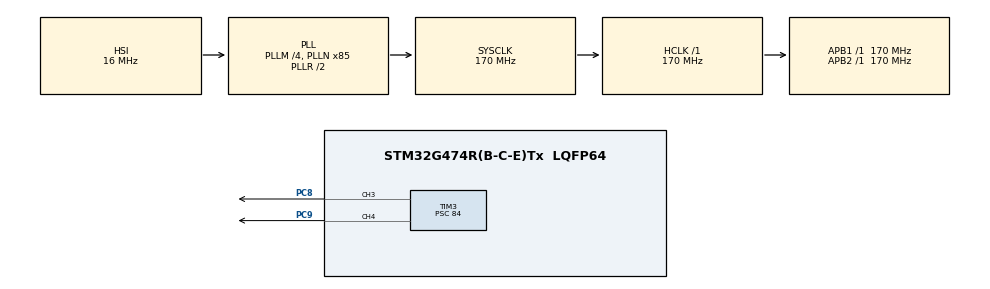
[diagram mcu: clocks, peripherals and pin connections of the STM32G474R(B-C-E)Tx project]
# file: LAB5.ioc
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Mcu.Family=STM32G4
Mcu.Name=STM32G474R(B-C-E)Tx
Mcu.Package=LQFP64
NVIC.PriorityGroup=NVIC_PRIORITYGROUP_4
PA13.GPIO_Label=T_SWDIO
PA13.Signal=SYS_JTMS-SWDIO
PA14.GPIO_Label=T_SWCLK
PA14.Signal=SYS_JTCK-SWCLK
PA2.GPIO_Label=LPUART1_TX [STLINKV3E_VCP_RX]
PA2.Signal=LPUART1_TX
PA3.GPIO_Label=LPUART1_RX [STLINKV3E_VCP_TX]
PA3.Signal=LPUART1_RX
PB3.GPIO_Label=T_SWO
PB3.Signal=SYS_JTDO-SWO
PC14-OSC32_IN.GPIO_Label=RCC_OSC32_IN
PC14-OSC32_IN.Signal=RCC_OSC32_IN
PC15-OSC32_OUT.GPIO_Label=RCC_OSC32_OUT
PC15-OSC32_OUT.Signal=RCC_OSC32_OUT
PC8.Signal=S_TIM3_CH3
PC9.Signal=S_TIM3_CH4
PF0-OSC_IN.GPIO_Label=RCC_OSC_IN
PF0-OSC_IN.Signal=RCC_OSC_IN
PF1-OSC_OUT.GPIO_Label=RCC_OSC_OUT
PF1-OSC_OUT.Signal=RCC_OSC_OUT
ProjectManager.HeapSize=0x200
ProjectManager.StackSize=0x400
ProjectManager.TargetToolchain=STM32CubeIDE
RCC.ADC12Freq_Value=170000000
RCC.ADC345Freq_Value=170000000
RCC.AHBFreq_Value=170000000
RCC.APB1Freq_Value=170000000
RCC.APB1TimFreq_Value=170000000
RCC.APB2Freq_Value=170000000
RCC.APB2TimFreq_Value=170000000
RCC.CortexFreq_Value=170000000
RCC.EXTERNAL_CLOCK_VALUE=12288000
RCC.HCLKFreq_Value=170000000
RCC.HSE_VALUE=24000000
RCC.HSI48_VALUE=48000000
RCC.HSI_VALUE=16000000
RCC.LSE_VALUE=32768
RCC.PLLM=RCC_PLLM_DIV4
RCC.PLLN=85
RCC.RTCClockSelection=RCC_RTCCLKSOURCE_LSE
RCC.SYSCLKFreq_VALUE=170000000
RCC.SYSCLKSource=RCC_SYSCLKSOURCE_PLLCLK
RCC.USBFreq_Value=170000000
RCC.VCOOutputFreq_Value=340000000
SH.S_TIM3_CH3.0=TIM3_CH3,PWM Generation3 CH3
SH.S_TIM3_CH4.0=TIM3_CH4,PWM Generation4 CH4
TIM3.Channel-PWM\ Generation3\ CH3=TIM_CHANNEL_3
TIM3.Channel-PWM\ Generation4\ CH4=TIM_CHANNEL_4
TIM3.PeriodNoDither=19999
TIM3.Prescaler=84
TIM3.PulseNoDither_3=4000
TIM3.PulseNoDither_4=16000
VP_SYS_VS_DBSignals.Mode=DisableDeadBatterySignals
VP_TIM3_VS_ClockSourceINT.Mode=Internal
board=NUCLEO-G474RE

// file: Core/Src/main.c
/* USER CODE BEGIN Header */
/**
  ******************************************************************************
  * @file           : main.c
  * @brief          : Main program body
  ******************************************************************************
  * @attention
  *
  * Copyright (c) 2026 STMicroelectronics.
  * All rights reserved.
  *
  * This software is licensed under terms that can be found in the LICENSE file
  * in the root directory of this software component.
  * If no LICENSE file comes with this software, it is provided AS-IS.
  *
  ******************************************************************************
  */
/* USER CODE END Header */
#include "main.h"

TIM_HandleTypeDef htim3;

void SystemClock_Config(void);
static void MX_GPIO_Init(void);
static void MX_TIM3_Init(void);

int main(void)
{

  /* MCU Configuration--------------------------------------------------------*/

  /* Reset of all peripherals, Initializes the Flash interface and the Systick. */
  HAL_Init();

  /* Configure the system clock */
  SystemClock_Config();

  /* Initialize all configured peripherals */
  MX_GPIO_Init();
  MX_TIM3_Init();
  /* USER CODE BEGIN 2 */
  HAL_TIM_PWM_Start(&htim3, TIM_CHANNEL_3);  // 啟動 TIM3_CH3 (PC8) 的 PWM 輸出

    uint32_t previous_time = 0;                // 記錄上次更新亮度的時間 (毫秒)
    int32_t pwm_value = 0;                     // 記錄目前的 CCR (亮度) 數值
    int32_t step = 200;
  /* USER CODE END 2 */

  /* Infinite loop */
  while (1)
  {

    /* USER CODE BEGIN 3 */
	  uint32_t current_time = HAL_GetTick();   // 取得目前的系統時間 (單位: 毫秒)

	      // 每 10 毫秒更新一次 PWM 數值 (非阻塞式寫法)
	      if (current_time - previous_time >= 10)
	      {
	        previous_time = current_time;          // 更新時間紀錄，為下一次 10ms 準備

	        pwm_value += step;                     // 將當前亮度加上步進值 (變亮或變暗)

	        // 如果亮度超過或等於 ARR 最大值 (19999)，或者降到 0 以下
	        if (pwm_value >= 19999)
	        {
	          pwm_value = 19999;                   // 限制最大值不超過 ARR
	          step = -step;                        // 反轉方向，準備變暗
	        }
	        else if (pwm_value <= 0)
	        {
	          pwm_value = 0;                       // 限制最小值不低於 0
	          step = -step;                        // 反轉方向，準備變亮
	        }

	        // 將計算好的新亮度寫入 CCR 暫存器，PWM 會即時改變 Duty Cycle
	        // (注意：這行已經正確包在 10ms 的 if 判斷式裡面了)
	        __HAL_TIM_SET_COMPARE(&htim3, TIM_CHANNEL_3, pwm_value);
	      }
  }
  /* USER CODE END 3 */
}

void SystemClock_Config(void)
{
  RCC_OscInitTypeDef RCC_OscInitStruct = {0};
  RCC_ClkInitTypeDef RCC_ClkInitStruct = {0};

  /** Configure the main internal regulator output voltage
  */
  HAL_PWREx_ControlVoltageScaling(PWR_REGULATOR_VOLTAGE_SCALE1_BOOST);

  /** Initializes the RCC Oscillators according to the specified parameters
  * in the RCC_OscInitTypeDef structure.
  */
  RCC_OscInitStruct.OscillatorType = RCC_OSCILLATORTYPE_HSI;
  RCC_OscInitStruct.HSIState = RCC_HSI_ON;
  RCC_OscInitStruct.HSICalibrationValue = RCC_HSICALIBRATION_DEFAULT;
  RCC_OscInitStruct.PLL.PLLState = RCC_PLL_ON;
  RCC_OscInitStruct.PLL.PLLSource = RCC_PLLSOURCE_HSI;
  RCC_OscInitStruct.PLL.PLLM = RCC_PLLM_DIV4;
  RCC_OscInitStruct.PLL.PLLN = 85;
  RCC_OscInitStruct.PLL.PLLP = RCC_PLLP_DIV2;
  RCC_OscInitStruct.PLL.PLLQ = RCC_PLLQ_DIV2;
  RCC_OscInitStruct.PLL.PLLR = RCC_PLLR_DIV2;
  if (HAL_RCC_OscConfig(&RCC_OscInitStruct) != HAL_OK)
  {
    Error_Handler();
  }

  /** Initializes the CPU, AHB and APB buses clocks
  */
  RCC_ClkInitStruct.ClockType = RCC_CLOCKTYPE_HCLK|RCC_CLOCKTYPE_SYSCLK
                              |RCC_CLOCKTYPE_PCLK1|RCC_CLOCKTYPE_PCLK2;
  RCC_ClkInitStruct.SYSCLKSource = RCC_SYSCLKSOURCE_PLLCLK;
  RCC_ClkInitStruct.AHBCLKDivider = RCC_SYSCLK_DIV1;
  RCC_ClkInitStruct.APB1CLKDivider = RCC_HCLK_DIV1;
  RCC_ClkInitStruct.APB2CLKDivider = RCC_HCLK_DIV1;

  if (HAL_RCC_ClockConfig(&RCC_ClkInitStruct, FLASH_LATENCY_4) != HAL_OK)
  {
    Error_Handler();
  }
}

static void MX_TIM3_Init(void)
{

  TIM_ClockConfigTypeDef sClockSourceConfig = {0};
  TIM_MasterConfigTypeDef sMasterConfig = {0};
  TIM_OC_InitTypeDef sConfigOC = {0};

  htim3.Instance = TIM3;
  htim3.Init.Prescaler = 84;
  htim3.Init.CounterMode = TIM_COUNTERMODE_UP;
  htim3.Init.Period = 19999;
  htim3.Init.ClockDivision = TIM_CLOCKDIVISION_DIV1;
  htim3.Init.AutoReloadPreload = TIM_AUTORELOAD_PRELOAD_DISABLE;
  if (HAL_TIM_Base_Init(&htim3) != HAL_OK)
  {
    Error_Handler();
  }
  sClockSourceConfig.ClockSource = TIM_CLOCKSOURCE_INTERNAL;
  if (HAL_TIM_ConfigClockSource(&htim3, &sClockSourceConfig) != HAL_OK)
  {
    Error_Handler();
  }
  if (HAL_TIM_PWM_Init(&htim3) != HAL_OK)
  {
    Error_Handler();
  }
  sMasterConfig.MasterOutputTrigger = TIM_TRGO_RESET;
  sMasterConfig.MasterSlaveMode = TIM_MASTERSLAVEMODE_DISABLE;
  if (HAL_TIMEx_MasterConfigSynchronization(&htim3, &sMasterConfig) != HAL_OK)
  {
    Error_Handler();
  }
  sConfigOC.OCMode = TIM_OCMODE_PWM1;
  sConfigOC.Pulse = 4000;
  sConfigOC.OCPolarity = TIM_OCPOLARITY_HIGH;
  sConfigOC.OCFastMode = TIM_OCFAST_DISABLE;
  if (HAL_TIM_PWM_ConfigChannel(&htim3, &sConfigOC, TIM_CHANNEL_3) != HAL_OK)
  {
    Error_Handler();
  }
  sConfigOC.Pulse = 16000;
  if (HAL_TIM_PWM_ConfigChannel(&htim3, &sConfigOC, TIM_CHANNEL_4) != HAL_OK)
  {
    Error_Handler();
  }
  HAL_TIM_MspPostInit(&htim3);

}

static void MX_GPIO_Init(void)
{
  GPIO_InitTypeDef GPIO_InitStruct = {0};

  /* GPIO Ports Clock Enable */
  __HAL_RCC_GPIOC_CLK_ENABLE();
  __HAL_RCC_GPIOF_CLK_ENABLE();
  __HAL_RCC_GPIOA_CLK_ENABLE();
  __HAL_RCC_GPIOB_CLK_ENABLE();

  /*Configure GPIO pins : LPUART1_TX_Pin LPUART1_RX_Pin */
  GPIO_InitStruct.Pin = LPUART1_TX_Pin|LPUART1_RX_Pin;
  GPIO_InitStruct.Mode = GPIO_MODE_AF_PP;
  GPIO_InitStruct.Pull = GPIO_NOPULL;
  GPIO_InitStruct.Speed = GPIO_SPEED_FREQ_LOW;
  GPIO_InitStruct.Alternate = GPIO_AF12_LPUART1;
  HAL_GPIO_Init(GPIOA, &GPIO_InitStruct);

}

void Error_Handler(void)
{
  __disable_irq();
  while (1)
  {
  }
}
